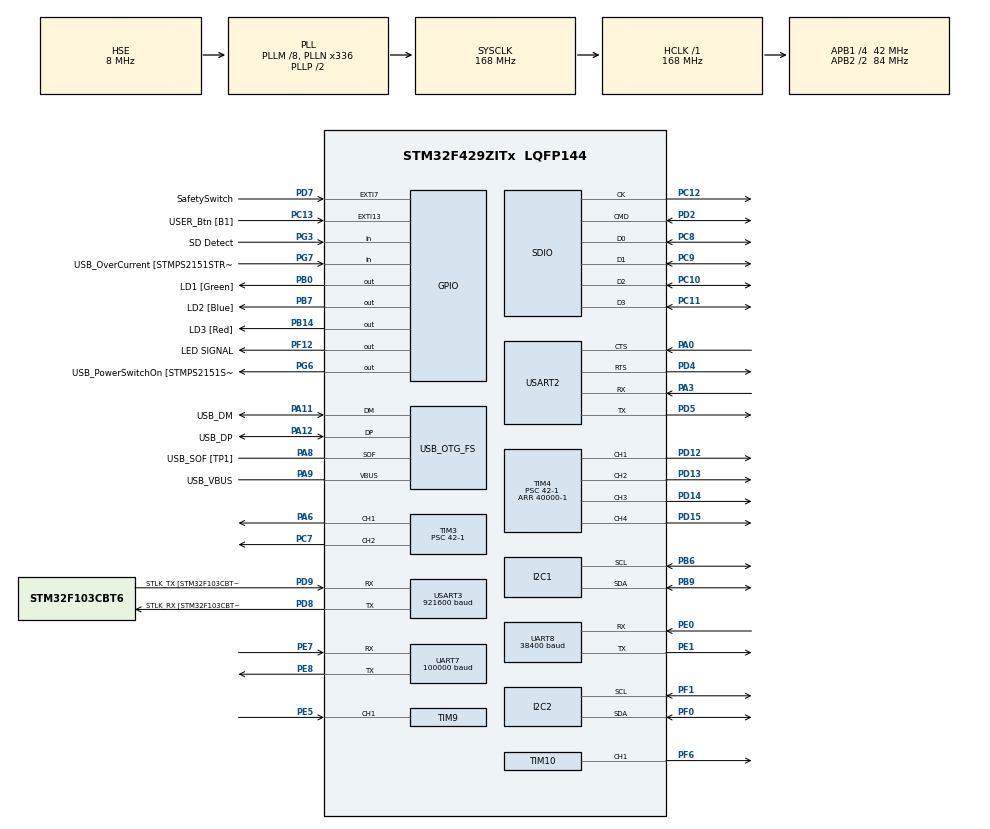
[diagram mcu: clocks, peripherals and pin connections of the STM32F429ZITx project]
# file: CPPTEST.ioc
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Dma.I2C1_RX.1.Direction=DMA_PERIPH_TO_MEMORY
Dma.I2C1_RX.1.FIFOMode=DMA_FIFOMODE_DISABLE
Dma.I2C1_RX.1.Instance=DMA1_Stream5
Dma.I2C1_RX.1.MemDataAlignment=DMA_MDATAALIGN_BYTE
Dma.I2C1_RX.1.MemInc=DMA_MINC_ENABLE
Dma.I2C1_RX.1.Mode=DMA_NORMAL
Dma.I2C1_RX.1.PeriphDataAlignment=DMA_PDATAALIGN_BYTE
Dma.I2C1_RX.1.PeriphInc=DMA_PINC_DISABLE
Dma.I2C1_RX.1.Priority=DMA_PRIORITY_LOW
Dma.Request0=UART7_RX
Dma.Request1=I2C1_RX
Dma.Request2=UART8_RX
Dma.Request3=SDIO_RX
Dma.Request4=SDIO_TX
Dma.SDIO_RX.3.Direction=DMA_PERIPH_TO_MEMORY
Dma.SDIO_RX.3.FIFOMode=DMA_FIFOMODE_ENABLE
Dma.SDIO_RX.3.FIFOThreshold=DMA_FIFO_THRESHOLD_FULL
Dma.SDIO_RX.3.Instance=DMA2_Stream3
Dma.SDIO_RX.3.MemBurst=DMA_MBURST_INC4
Dma.SDIO_RX.3.MemDataAlignment=DMA_MDATAALIGN_WORD
Dma.SDIO_RX.3.MemInc=DMA_MINC_ENABLE
Dma.SDIO_RX.3.Mode=DMA_PFCTRL
Dma.SDIO_RX.3.PeriphBurst=DMA_PBURST_INC4
Dma.SDIO_RX.3.PeriphDataAlignment=DMA_PDATAALIGN_WORD
Dma.SDIO_RX.3.PeriphInc=DMA_PINC_DISABLE
Dma.SDIO_RX.3.Priority=DMA_PRIORITY_LOW
Dma.SDIO_TX.4.Direction=DMA_MEMORY_TO_PERIPH
Dma.SDIO_TX.4.FIFOMode=DMA_FIFOMODE_ENABLE
Dma.SDIO_TX.4.FIFOThreshold=DMA_FIFO_THRESHOLD_FULL
Dma.SDIO_TX.4.Instance=DMA2_Stream6
Dma.SDIO_TX.4.MemBurst=DMA_MBURST_INC4
Dma.SDIO_TX.4.MemDataAlignment=DMA_MDATAALIGN_WORD
Dma.SDIO_TX.4.MemInc=DMA_MINC_ENABLE
Dma.SDIO_TX.4.Mode=DMA_PFCTRL
Dma.SDIO_TX.4.PeriphBurst=DMA_PBURST_INC4
Dma.SDIO_TX.4.PeriphDataAlignment=DMA_PDATAALIGN_WORD
Dma.SDIO_TX.4.PeriphInc=DMA_PINC_DISABLE
Dma.SDIO_TX.4.Priority=DMA_PRIORITY_LOW
Dma.UART7_RX.0.Direction=DMA_PERIPH_TO_MEMORY
Dma.UART7_RX.0.FIFOMode=DMA_FIFOMODE_DISABLE
Dma.UART7_RX.0.Instance=DMA1_Stream3
Dma.UART7_RX.0.MemDataAlignment=DMA_MDATAALIGN_BYTE
Dma.UART7_RX.0.MemInc=DMA_MINC_ENABLE
Dma.UART7_RX.0.Mode=DMA_CIRCULAR
Dma.UART7_RX.0.PeriphDataAlignment=DMA_PDATAALIGN_BYTE
Dma.UART7_RX.0.PeriphInc=DMA_PINC_DISABLE
Dma.UART7_RX.0.Priority=DMA_PRIORITY_LOW
Dma.UART8_RX.2.Direction=DMA_PERIPH_TO_MEMORY
Dma.UART8_RX.2.FIFOMode=DMA_FIFOMODE_DISABLE
Dma.UART8_RX.2.Instance=DMA1_Stream6
Dma.UART8_RX.2.MemDataAlignment=DMA_MDATAALIGN_BYTE
Dma.UART8_RX.2.MemInc=DMA_MINC_ENABLE
Dma.UART8_RX.2.Mode=DMA_CIRCULAR
Dma.UART8_RX.2.PeriphDataAlignment=DMA_PDATAALIGN_BYTE
Dma.UART8_RX.2.PeriphInc=DMA_PINC_DISABLE
Dma.UART8_RX.2.Priority=DMA_PRIORITY_LOW
FATFS.BSP.number=1
FATFS._CODE_PAGE=1
FATFS._MAX_SS=4096
FATFS0.BSP.STBoard=false
FATFS0.BSP.api=Unknown
FATFS0.BSP.i2caddr=0
FATFS0.BSP.instance=PG3
FATFS0.BSP.ip=GPIO
FATFS0.BSP.mode=Input
FATFS0.BSP.name=Detect_SDIO
FATFS0.BSP.solution=PG3
FREERTOS.HEAP_NUMBER=4
FREERTOS.Tasks01=defaultTask,24,128,StartDefaultTask,Default,NULL,Dynamic,NULL,NULL
FREERTOS.configENABLE_FPU=1
I2C1.I2C_Mode=I2C_Fast
I2C2.I2C_Mode=I2C_Fast
Mcu.Family=STM32F4
Mcu.Name=STM32F429ZITx
Mcu.Package=LQFP144
NVIC.DMA1_Stream3_IRQn=true\:5\:0\:false\:true\:true\:7\:true\:false\:true
NVIC.DMA1_Stream5_IRQn=true\:5\:0\:true\:true\:true\:9\:false\:false\:true
NVIC.DMA1_Stream6_IRQn=true\:5\:0\:false\:true\:true\:8\:true\:false\:true
NVIC.DMA2_Stream3_IRQn=true\:15\:0\:true\:true\:true\:10\:true\:false\:true
NVIC.DMA2_Stream6_IRQn=true\:15\:0\:true\:true\:true\:11\:true\:false\:true
NVIC.I2C1_ER_IRQn=true\:5\:0\:false\:true\:true\:2\:true\:true\:true
NVIC.I2C1_EV_IRQn=true\:5\:0\:false\:true\:true\:1\:true\:true\:true
NVIC.I2C2_ER_IRQn=true\:5\:0\:false\:true\:true\:5\:true\:true\:true
NVIC.I2C2_EV_IRQn=true\:5\:0\:false\:true\:true\:4\:true\:true\:true
NVIC.PriorityGroup=NVIC_PRIORITYGROUP_4
NVIC.SDIO_IRQn=true\:15\:0\:true\:true\:true\:6\:true\:true\:true
NVIC.TIM1_BRK_TIM9_IRQn=true\:5\:0\:false\:true\:true\:12\:true\:true\:true
NVIC.TIM2_IRQn=true\:5\:0\:false\:true\:true\:13\:true\:true\:true
NVIC.TIM6_DAC_IRQn=true\:0\:0\:false\:false\:true\:false\:false\:true
NVIC.TimeBase=TIM6_DAC_IRQn
NVIC.TimeBaseIP=TIM6
NVIC.UART7_IRQn=true\:5\:0\:false\:true\:true\:3\:true\:true\:true
NVIC.UART8_IRQn=true\:5\:0\:true\:true\:true\:14\:true\:true\:true
NVIC.USART3_IRQn=true\:5\:0\:false\:false\:true\:true\:true\:true
PA0/WKUP.Mode=CTS_RTS
PA0/WKUP.Signal=USART2_CTS
PA1.GPIO_Label=RMII_REF_CLK [LAN8742A-CZ-TR_REFCLK0]
PA1.Signal=ETH_REF_CLK
PA10.GPIO_Label=USB_ID
PA10.Signal=USB_OTG_FS_ID
PA11.GPIO_Label=USB_DM
PA11.Mode=Device_Only
PA11.Signal=USB_OTG_FS_DM
PA12.GPIO_Label=USB_DP
PA12.Mode=Device_Only
PA12.Signal=USB_OTG_FS_DP
PA13.GPIO_Label=TMS
PA13.Mode=Serial_Wire
PA13.Signal=SYS_JTMS-SWDIO
PA14.GPIO_Label=TCK
PA14.Mode=Serial_Wire
PA14.Signal=SYS_JTCK-SWCLK
PA2.GPIO_Label=RMII_MDIO [LAN8742A-CZ-TR_MDIO]
PA2.Signal=ETH_MDIO
PA3.Mode=Asynchronous
PA3.Signal=USART2_RX
PA6.Signal=S_TIM3_CH1
PA7.GPIO_Label=RMII_CRS_DV [LAN8742A-CZ-TR_CRS_DV]
PA7.Signal=ETH_CRS_DV
PA8.GPIO_Label=USB_SOF [TP1]
PA8.Mode=Activate_SOF_FS
PA8.Signal=USB_OTG_FS_SOF
PA9.GPIO_Label=USB_VBUS
PA9.Mode=Activate_VBUS
PA9.Signal=USB_OTG_FS_VBUS
PB0.GPIO_Label=LD1 [Green]
PB0.Signal=GPIO_Output
PB13.GPIO_Label=RMII_TXD1 [LAN8742A-CZ-TR_TXD1]
PB13.Signal=ETH_TXD1
PB14.GPIO_Label=LD3 [Red]
PB14.Signal=GPIO_Output
PB6.Mode=I2C
PB6.Signal=I2C1_SCL
PB7.GPIO_Label=LD2 [Blue]
PB7.Signal=GPIO_Output
PB9.Mode=I2C
PB9.Signal=I2C1_SDA
PC1.GPIO_Label=RMII_MDC [LAN8742A-CZ-TR_MDC]
PC1.Signal=ETH_MDC
PC10.GPIO_PuPd=GPIO_PULLUP
PC10.Mode=SD_4_bits_Wide_bus
PC10.Signal=SDIO_D2
PC11.GPIO_PuPd=GPIO_PULLUP
PC11.Mode=SD_4_bits_Wide_bus
PC11.Signal=SDIO_D3
PC12.Mode=SD_4_bits_Wide_bus
PC12.Signal=SDIO_CK
PC13.GPIO_Label=USER_Btn [B1]
PC13.Signal=GPXTI13
PC14/OSC32_IN.Mode=LSE-External-Clock-Source
PC14/OSC32_IN.Signal=RCC_OSC32_IN
PC15/OSC32_OUT.Mode=LSE-External-Clock-Source
PC15/OSC32_OUT.Signal=RCC_OSC32_OUT
PC4.GPIO_Label=RMII_RXD0 [LAN8742A-CZ-TR_RXD0]
PC4.Signal=ETH_RXD0
PC5.GPIO_Label=RMII_RXD1 [LAN8742A-CZ-TR_RXD1]
PC5.Signal=ETH_RXD1
PC7.Signal=S_TIM3_CH2
PC8.GPIO_PuPd=GPIO_PULLUP
PC8.Mode=SD_4_bits_Wide_bus
PC8.Signal=SDIO_D0
PC9.GPIO_PuPd=GPIO_PULLUP
PC9.Mode=SD_4_bits_Wide_bus
PC9.Signal=SDIO_D1
PD12.Signal=S_TIM4_CH1
PD13.Signal=S_TIM4_CH2
PD14.Signal=S_TIM4_CH3
PD15.Signal=S_TIM4_CH4
PD2.GPIO_PuPd=GPIO_PULLUP
PD2.Mode=SD_4_bits_Wide_bus
PD2.Signal=SDIO_CMD
PD4.Mode=CTS_RTS
PD4.Signal=USART2_RTS
PD5.Mode=Asynchronous
PD5.Signal=USART2_TX
PD7.GPIO_Label=SafetySwitch
PD7.GPIO_PuPd=GPIO_PULLDOWN
PD7.Signal=GPXTI7
PD8.GPIO_Label=STLK_RX [STM32F103CBT6_PA3]
PD8.Mode=Asynchronous
PD8.Signal=USART3_TX
PD9.GPIO_Label=STLK_TX [STM32F103CBT6_PA2]
PD9.Mode=Asynchronous
PD9.Signal=USART3_RX
PE0.Mode=Asynchronous
PE0.Signal=UART8_RX
PE1.Mode=Asynchronous
PE1.Signal=UART8_TX
PE5.Signal=S_TIM9_CH1
PE7.Mode=Asynchronous
PE7.Signal=UART7_RX
PE8.Mode=Asynchronous
PE8.Signal=UART7_TX
PF0.Mode=I2C
PF0.Signal=I2C2_SDA
PF1.Mode=I2C
PF1.Signal=I2C2_SCL
PF12.GPIO_Label=LED SIGNAL
PF12.GPIO_PuPd=GPIO_PULLDOWN
PF12.Signal=GPIO_Output
PF6.Signal=S_TIM10_CH1
PG11.GPIO_Label=RMII_TX_EN [LAN8742A-CZ-TR_TXEN]
PG11.Signal=ETH_TX_EN
PG13.GPIO_Label=RMII_TXD0 [LAN8742A-CZ-TR_TXD0]
PG13.Signal=ETH_TXD0
PG3.GPIO_Label=SD Detect
PG3.Signal=GPIO_Input
PG6.GPIO_Label=USB_PowerSwitchOn [STMPS2151STR_EN]
PG6.Signal=GPIO_Output
PG7.GPIO_Label=USB_OverCurrent [STMPS2151STR_FAULT]
PG7.Signal=GPIO_Input
PH0/OSC_IN.GPIO_Label=MCO [STM32F103CBT6_PA8]
PH0/OSC_IN.Mode=HSE-External-Oscillator
PH0/OSC_IN.Signal=RCC_OSC_IN
PH1/OSC_OUT.Mode=HSE-External-Oscillator
PH1/OSC_OUT.Signal=RCC_OSC_OUT
ProjectManager.HeapSize=0x200
ProjectManager.StackSize=0x400
ProjectManager.TargetToolchain=STM32CubeIDE
RCC.48MHZClocksFreq_Value=48000000
RCC.AHBFreq_Value=168000000
RCC.APB1CLKDivider=RCC_HCLK_DIV4
RCC.APB1Freq_Value=42000000
RCC.APB1TimFreq_Value=84000000
RCC.APB2CLKDivider=RCC_HCLK_DIV2
RCC.APB2Freq_Value=84000000
RCC.APB2TimFreq_Value=168000000
RCC.CortexFreq_Value=168000000
RCC.HCLKFreq_Value=168000000
RCC.HSE_VALUE=8000000
RCC.HSI_VALUE=16000000
RCC.LSE_VALUE=32768
RCC.PLLM=8
RCC.PLLMUL=RCC_PLL_MUL9
RCC.PLLN=336
RCC.PLLQ=7
RCC.PRESCALERUSB=RCC_USBCLKSOURCE_PLL_DIV1_5
RCC.SYSCLKFreq_VALUE=168000000
RCC.SYSCLKSource=RCC_SYSCLKSOURCE_PLLCLK
RCC.SYSCLKSourceVirtual=RCC_SYSCLKSOURCE_PLLCLK
RCC.USBFreq_Value=48000000
RCC.VCOOutputFreq_Value=336000000
SH.S_TIM10_CH1.0=TIM10_CH1,PWM Generation1 CH1
SH.S_TIM3_CH1.0=TIM3_CH1,PWM Generation1 CH1
SH.S_TIM3_CH2.0=TIM3_CH2,PWM Generation2 CH2
SH.S_TIM4_CH1.0=TIM4_CH1,PWM Generation1 CH1
SH.S_TIM4_CH2.0=TIM4_CH2,PWM Generation2 CH2
SH.S_TIM4_CH3.0=TIM4_CH3,PWM Generation3 CH3
SH.S_TIM4_CH4.0=TIM4_CH4,PWM Generation4 CH4
SH.S_TIM9_CH1.0=TIM9_CH1,Input_Capture1_from_TI1
SH.S_TIM9_CH1.1=TIM9_CH1,Input_Capture2_from_TI1
TIM10.Channel=TIM_CHANNEL_1
TIM10.Period=1000-1
TIM10.Prescaler=168-1
TIM10.Pulse=500
TIM2.Period=4294967296-1
TIM2.Prescaler=84-1
TIM3.Channel-PWM\ Generation1\ CH1=TIM_CHANNEL_1
TIM3.Channel-PWM\ Generation2\ CH2=TIM_CHANNEL_2
TIM3.Period=40000-1
TIM3.Prescaler=42-1
TIM4.Channel-PWM\ Generation1\ CH1=TIM_CHANNEL_1
TIM4.Channel-PWM\ Generation2\ CH2=TIM_CHANNEL_2
TIM4.Channel-PWM\ Generation3\ CH3=TIM_CHANNEL_3
TIM4.Channel-PWM\ Generation4\ CH4=TIM_CHANNEL_4
TIM4.Period=40000-1
TIM4.Prescaler=42-1
TIM9.Channel-Input_Capture1_from_TI1=TIM_CHANNEL_1
TIM9.Channel-Input_Capture2_from_TI1=TIM_CHANNEL_2
TIM9.ICFilter_CH1=15
TIM9.ICPolarity_CH2=TIM_INPUTCHANNELPOLARITY_FALLING
TIM9.Period=65536-1
TIM9.Prescaler=168-1
UART7.BaudRate=100000
UART7.Parity=PARITY_EVEN
UART7.StopBits=UART_STOPBITS_2
UART7.VirtualMode=Asynchronous
UART7.WordLength=WORDLENGTH_9B
UART8.BaudRate=38400
UART8.VirtualMode=Asynchronous
USART2.VirtualMode=VM_ASYNC
USART3.BaudRate=921600
USART3.VirtualMode=VM_ASYNC
USB_OTG_FS.VirtualMode=Device_Only
VP_FATFS_VS_SDIO.Mode=SDIO
VP_FREERTOS_VS_CMSIS_V2.Mode=CMSIS_V2
VP_SYS_VS_tim6.Mode=TIM6
VP_TIM10_VS_ClockSourceINT.Mode=Enable_Timer
VP_TIM2_VS_ClockSourceINT.Mode=Internal
VP_TIM3_VS_ClockSourceINT.Mode=Internal
VP_TIM4_VS_ClockSourceINT.Mode=Internal
board=NUCLEO-F429ZI

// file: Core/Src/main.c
/* USER CODE BEGIN Header */
/**
  ******************************************************************************
  * @file           : main.c
  * @brief          : Main program body
  ******************************************************************************
  * @attention
  *
  * <h2><center>&copy; Copyright (c) 2020 STMicroelectronics.
  * All rights reserved.</center></h2>
  *
  * This software component is licensed by ST under BSD 3-Clause license,
  * the "License"; You may not use this file except in compliance with the
  * License. You may obtain a copy of the License at:
  *                        opensource.org/licenses/BSD-3-Clause
  *
  ******************************************************************************
  */
/* USER CODE END Header */

#include "main.h"
#include "cmsis_os.h"
#include "dma.h"
#include "fatfs.h"
#include "i2c.h"
#include "sdio.h"
#include "tim.h"
#include "usart.h"
#include "usb_otg.h"
#include "gpio.h"

/* USER CODE BEGIN Includes */
#include "Usec.h"
/* USER CODE END Includes */

void SystemClock_Config(void);
void MX_FREERTOS_Init(void);
static void MX_NVIC_Init(void);

int main(void)
{

  /* MCU Configuration--------------------------------------------------------*/

  /* Reset of all peripherals, Initializes the Flash interface and the Systick. */
  HAL_Init();

  /* Configure the system clock */
  SystemClock_Config();

  /* Initialize all configured peripherals */
  MX_GPIO_Init();
  MX_DMA_Init();
  MX_USART3_UART_Init();
  MX_USB_OTG_FS_PCD_Init();
  MX_I2C1_Init();
  MX_TIM3_Init();
  MX_TIM4_Init();
  MX_UART7_Init();
  MX_USART2_UART_Init();
  MX_I2C2_Init();
  MX_TIM2_Init();
  MX_TIM10_Init();
  MX_UART8_Init();
  MX_SDIO_SD_Init();
  MX_FATFS_Init();
  MX_TIM9_Init();

  /* Initialize interrupts */
  MX_NVIC_Init();
  /* USER CODE BEGIN 2 */
  cppMain();
  /* USER CODE END 2 */

  /* Init scheduler */
  osKernelInitialize();  /* Call init function for freertos objects (in freertos.c) */
  MX_FREERTOS_Init();
  /* Start scheduler */
  osKernelStart();

  /* We should never get here as control is now taken by the scheduler */
  /* Infinite loop */
  /* USER CODE BEGIN WHILE */
  while (1)
  {
//	CppMain();
    /* USER CODE END WHILE */

  }
}

void SystemClock_Config(void)
{
  RCC_OscInitTypeDef RCC_OscInitStruct = {0};
  RCC_ClkInitTypeDef RCC_ClkInitStruct = {0};

  /** Configure the main internal regulator output voltage
  */
  __HAL_RCC_PWR_CLK_ENABLE();
  __HAL_PWR_VOLTAGESCALING_CONFIG(PWR_REGULATOR_VOLTAGE_SCALE1);
  /** Initializes the CPU, AHB and APB busses clocks
  */
  RCC_OscInitStruct.OscillatorType = RCC_OSCILLATORTYPE_HSE;
  RCC_OscInitStruct.HSEState = RCC_HSE_ON;
  RCC_OscInitStruct.PLL.PLLState = RCC_PLL_ON;
  RCC_OscInitStruct.PLL.PLLSource = RCC_PLLSOURCE_HSE;
  RCC_OscInitStruct.PLL.PLLM = 8;
  RCC_OscInitStruct.PLL.PLLN = 336;
  RCC_OscInitStruct.PLL.PLLP = RCC_PLLP_DIV2;
  RCC_OscInitStruct.PLL.PLLQ = 7;
  if (HAL_RCC_OscConfig(&RCC_OscInitStruct) != HAL_OK)
  {
    Error_Handler();
  }
  /** Initializes the CPU, AHB and APB busses clocks
  */
  RCC_ClkInitStruct.ClockType = RCC_CLOCKTYPE_HCLK|RCC_CLOCKTYPE_SYSCLK
                              |RCC_CLOCKTYPE_PCLK1|RCC_CLOCKTYPE_PCLK2;
  RCC_ClkInitStruct.SYSCLKSource = RCC_SYSCLKSOURCE_PLLCLK;
  RCC_ClkInitStruct.AHBCLKDivider = RCC_SYSCLK_DIV1;
  RCC_ClkInitStruct.APB1CLKDivider = RCC_HCLK_DIV4;
  RCC_ClkInitStruct.APB2CLKDivider = RCC_HCLK_DIV2;

  if (HAL_RCC_ClockConfig(&RCC_ClkInitStruct, FLASH_LATENCY_5) != HAL_OK)
  {
    Error_Handler();
  }
}

/**
  * @brief NVIC Configuration.
  * @retval None
  */
static void MX_NVIC_Init(void)
{
  /* I2C1_EV_IRQn interrupt configuration */
  HAL_NVIC_SetPriority(I2C1_EV_IRQn, 5, 0);
  HAL_NVIC_EnableIRQ(I2C1_EV_IRQn);
  /* I2C1_ER_IRQn interrupt configuration */
  HAL_NVIC_SetPriority(I2C1_ER_IRQn, 5, 0);
  HAL_NVIC_EnableIRQ(I2C1_ER_IRQn);
  /* UART7_IRQn interrupt configuration */
  HAL_NVIC_SetPriority(UART7_IRQn, 5, 0);
  HAL_NVIC_EnableIRQ(UART7_IRQn);
  /* I2C2_EV_IRQn interrupt configuration */
  HAL_NVIC_SetPriority(I2C2_EV_IRQn, 5, 0);
  HAL_NVIC_EnableIRQ(I2C2_EV_IRQn);
  /* I2C2_ER_IRQn interrupt configuration */
  HAL_NVIC_SetPriority(I2C2_ER_IRQn, 5, 0);
  HAL_NVIC_EnableIRQ(I2C2_ER_IRQn);
  /* SDIO_IRQn interrupt configuration */
  HAL_NVIC_SetPriority(SDIO_IRQn, 15, 0);
  HAL_NVIC_EnableIRQ(SDIO_IRQn);
  /* DMA1_Stream3_IRQn interrupt configuration */
  HAL_NVIC_SetPriority(DMA1_Stream3_IRQn, 5, 0);
  HAL_NVIC_EnableIRQ(DMA1_Stream3_IRQn);
  /* DMA1_Stream6_IRQn interrupt configuration */
  HAL_NVIC_SetPriority(DMA1_Stream6_IRQn, 5, 0);
  HAL_NVIC_EnableIRQ(DMA1_Stream6_IRQn);
  /* DMA1_Stream5_IRQn interrupt configuration */
  HAL_NVIC_SetPriority(DMA1_Stream5_IRQn, 5, 0);
  HAL_NVIC_EnableIRQ(DMA1_Stream5_IRQn);
  /* DMA2_Stream3_IRQn interrupt configuration */
  HAL_NVIC_SetPriority(DMA2_Stream3_IRQn, 15, 0);
  HAL_NVIC_EnableIRQ(DMA2_Stream3_IRQn);
  /* DMA2_Stream6_IRQn interrupt configuration */
  HAL_NVIC_SetPriority(DMA2_Stream6_IRQn, 15, 0);
  HAL_NVIC_EnableIRQ(DMA2_Stream6_IRQn);
  /* TIM1_BRK_TIM9_IRQn interrupt configuration */
  HAL_NVIC_SetPriority(TIM1_BRK_TIM9_IRQn, 5, 0);
  HAL_NVIC_EnableIRQ(TIM1_BRK_TIM9_IRQn);
  /* TIM2_IRQn interrupt configuration */
  HAL_NVIC_SetPriority(TIM2_IRQn, 5, 0);
  HAL_NVIC_EnableIRQ(TIM2_IRQn);
  /* UART8_IRQn interrupt configuration */
  HAL_NVIC_SetPriority(UART8_IRQn, 5, 0);
  HAL_NVIC_EnableIRQ(UART8_IRQn);
}

 /**
  * @brief  Period elapsed callback in non blocking mode
  * @note   This function is called  when TIM6 interrupt took place, inside
  * HAL_TIM_IRQHandler(). It makes a direct call to HAL_IncTick() to increment
  * a global variable "uwTick" used as application time base.
  * @param  htim : TIM handle
  * @retval None
  */
void HAL_TIM_PeriodElapsedCallback(TIM_HandleTypeDef *htim)
{
  /* USER CODE BEGIN Callback 0 */
	/* microseond timer */
  if(htim->Instance == TIM2){
	  msOverFlow();
  }
  /* USER CODE END Callback 0 */
  if (htim->Instance == TIM6) {
    HAL_IncTick();
  }
}

void Error_Handler(void)
{
}

/************************ (C) COPYRIGHT STMicroelectronics *****END OF FILE****/
